# KM1M7CF03 register map
Vendor: Nuvoton Technology Corporation Japan; Series: KM1M7CF; File version: 1.0.3
CPU: CM7 r1p2, little endian, MPU, FPU, double-precision FPU, I-cache, D-cache, ITCM, DTCM, 4 interrupt priority bits
Registers are 16-bit, access per field, no defined reset value unless marked. A register's access mark holds for its fields unless they carry their own. Offsets are from the block's base; [hi:lo] are bit positions; {n}, {i} and the like mark numbered series; 'fields as' and 'values as' point back to an identical list.

## _16TM — 16-bit Timer
Base 0x40051000
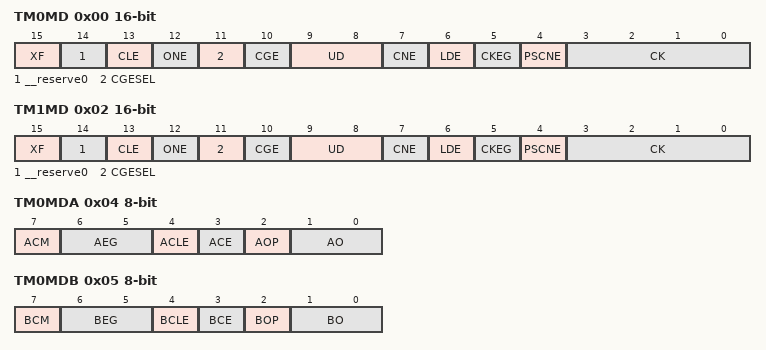
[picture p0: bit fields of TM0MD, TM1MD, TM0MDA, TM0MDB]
0x00 TM0MD — Timer 0 Mode Register
  [15] XF ro — Operation status of the timer n
  [14] __reserve0 ro — "0" is always read out.
  [13] CLE rw — Binary counter clear enable
  [12] ONE rw — Timer 1-shot operation enable
  [11] CGESEL rw — Timer count control selection
  [10] CGE rw — count clock mask enable
  [9:8] UD rw — Binary counter up/down selection
  [7] CNE rw — Timer n operation enable (*1)
  [6] LDE rw — Timer n binary counter initialization
  [5] CKEG rw — Clock Source Edge Selection
  [4] PSCNE rw — Prescaler operation enable
  [3:0] CK rw — Clock Source Selection
0x02 TM1MD — Timer 1 Mode Register
  fields as TM0MD
0x04 TM0MDA 8-bit rw — Timer 0 Compare/Capture A Mode Register
  [7] ACM — Compare A operation mode selection
  [6:5] AEG — Capture factor A edge selection
  [4] ACLE — Capture counter clear
  [3] ACE — Capture A operation enable
  [2] AOP — Timer output polarity
  [1:0] AO — Timer pin A output waveform selection
0x05 TM0MDB 8-bit rw — Timer 0 Compare/Capture B Mode Register
  [7] BCM — Compare B operation mode selection
  [6:5] BEG — Capture factor B edge selection
  [4] BCLE — Capture counter clear
  [3] BCE — Capture B operation enable
  [2] BOP — Timer output polarity
  [1:0] BO — Timer pin A output waveform selection
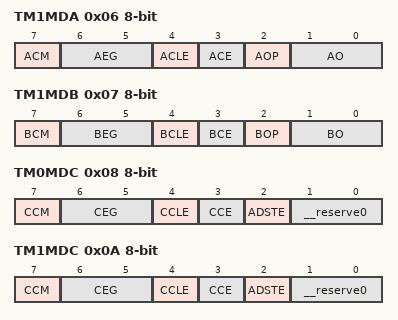
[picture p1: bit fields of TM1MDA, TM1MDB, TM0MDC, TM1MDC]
0x06 TM1MDA 8-bit rw — Timer 1 Compare/Capture A Mode Register
  fields as TM0MDA
0x07 TM1MDB 8-bit rw — Timer 1 Compare/Capture B Mode Register
  fields as TM0MDB
0x08 TM0MDC 8-bit — Timer 0 Compare/Capture C Mode Register
  [7] CCM rw — Compare C operation mode selection
  [6:5] CEG rw — Capture factor C edge selection
  [4] CCLE rw — Capture counter clear
  [3] CCE rw — Capture C operation enable
  [2] ADSTE rw — A/D start trigger enable
  [1:0] __reserve0 ro — "0" is always read out.
0x0A TM1MDC 8-bit — Timer 1 Compare/Capture C Mode Register
  fields as TM0MDC
0x10 TM0BC ro — Timer 0 Binary Counter
  [15:0] BC — Value of the binary counter is read out.
0x12 TM1BC ro — Timer 1 Binary Counter
  [15:0] BC — Value of the binary counter is read out.
0x14 TM0CA rw — Timer 0 Compare/Capture A Register
  [15:0] CA — Registers for compare A and capture A operation.
0x16 TM1CA rw — Timer 1 Compare/Capture A Register
  [15:0] CA — Registers for compare A and capture A operation.
0x18 TM0CB rw — Timer 0 Compare/Capture B Register
  [15:0] CB — Registers for compare B and capture B operation.
0x1A TM1CB rw — Timer 1 Compare/Capture B Register
  [15:0] CB — Registers for compare B and capture B operation.
0x1C TM0CC rw — Timer 0 Compare/Capture C Register
  [15:0] CC — Registers for compare C and capture C operation.
0x1E TM1CC rw — Timer 1 Compare/Capture C Register
  [15:0] CC — Registers for compare C and capture C operation.
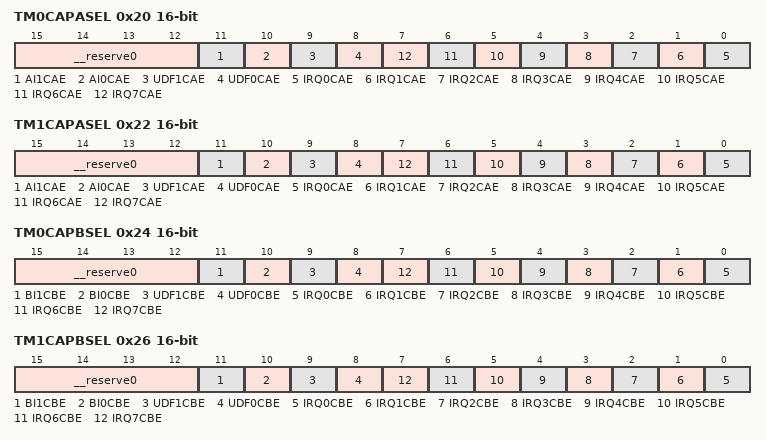
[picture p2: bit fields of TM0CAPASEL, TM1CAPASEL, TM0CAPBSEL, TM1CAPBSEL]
0x20 TM0CAPASEL — Timer 0 Capture A Factor Selection Register
  [15:12] __reserve0 ro — "0" is always read out.
  [11] AI1CAE rw — The capture A factor selection of timer n.
  [10] AI0CAE rw — The capture A factor selection of timer n.
  [9] UDF1CAE rw — The capture A factor selection of timer n.
  [8] UDF0CAE rw — The capture A factor selection of timer n.
  [n] IRQ{n}CAE rw (n=0..7) — The capture A factor selection of timer n.
0x22 TM1CAPASEL — Timer 1 Capture A Factor Selection Register
  fields as TM0CAPASEL
0x24 TM0CAPBSEL — Timer 0 Capture B Factor Selection Register
  [15:12] __reserve0 ro — "0" is always read out.
  [11] BI1CBE rw — The capture B factor selection of timer n
  [10] BI0CBE rw — The capture B factor selection of timer n
  [9] UDF1CBE rw — The capture B factor selection of timer n
  [8] UDF0CBE rw — The capture B factor selection of timer n
  [n] IRQ{n}CBE rw (n=0..7) — The capture B factor selection of timer n
0x26 TM1CAPBSEL — Timer 1 Capture B Factor Selection Register
  fields as TM0CAPBSEL
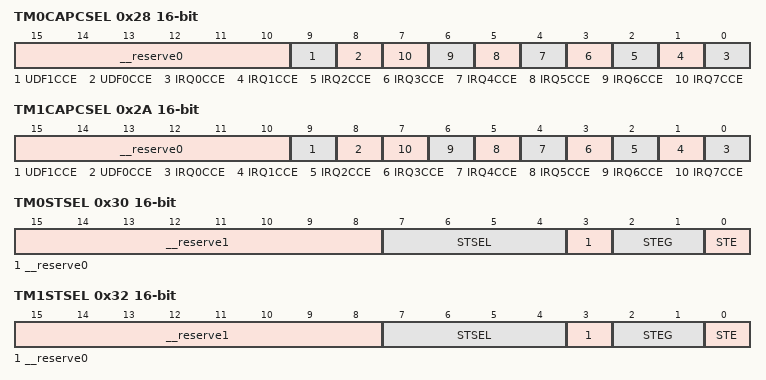
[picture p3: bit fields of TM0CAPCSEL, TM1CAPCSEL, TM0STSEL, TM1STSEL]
0x28 TM0CAPCSEL — Timer 0 Capture C Factor Selection Register
  [15:10] __reserve0 ro — "0" is always read out.
  [9] UDF1CCE rw — The capture C factor selection of timer n
  [8] UDF0CCE rw — The capture C factor selection of timer n
  [n] IRQ{n}CCE rw (n=0..7) — The capture C factor selection of timer n
0x2A TM1CAPCSEL — Timer 1 Capture C Factor Selection Register
  fields as TM0CAPCSEL
0x30 TM0STSEL — Timer 0 Start Trigger Factor Selection Register
  [15:8] __reserve1 ro — "0" is always read out.
  [7:4] STSEL rw — Start trigger factor selection
  [3] __reserve0 ro — "0" is always read out.
  [2:1] STEG rw — Start trigger factor edge selection
  [0] STE rw — Timer n start trigger enable
0x32 TM1STSEL — Timer 1 Start Trigger Factor Selection Register
  fields as TM0STSEL
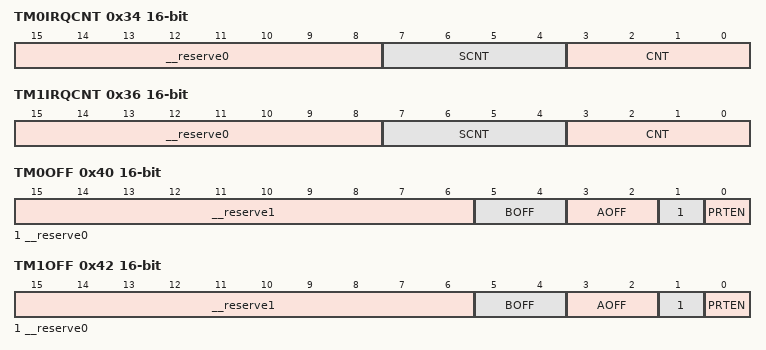
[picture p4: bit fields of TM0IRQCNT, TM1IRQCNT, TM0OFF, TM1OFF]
0x34 TM0IRQCNT — Timer 0 Interrupt Output Control Register
  [15:8] __reserve0 ro — "0" is always read out.
  [7:4] SCNT rw — Number of times setting for timer n compare/capture C interrupt (First time)
  [3:0] CNT rw — Number of times setting for timer n compare/capture C interrupt (Second time or later)
0x36 TM1IRQCNT — Timer 1 Interrupt Output Control Register
  fields as TM0IRQCNT
0x40 TM0OFF — Timer 0 Pin Protection Control Register
  [15:6] __reserve1 ro — "0" is always read out.
  [5:4] BOFF rw — TMnB pin output protection
  [3:2] AOFF rw — TMnA pin output protection
  [1] __reserve0 ro — "0" is always read out.
  [0] PRTEN rw — Pin protection enable
0x42 TM1OFF — Timer 1 Pin Protection Control Register
  fields as TM0OFF
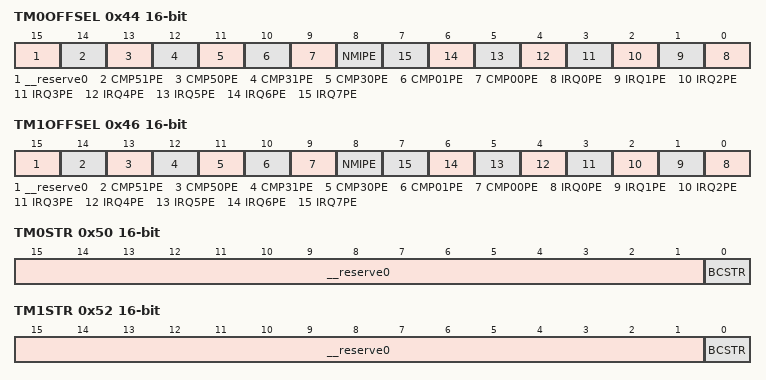
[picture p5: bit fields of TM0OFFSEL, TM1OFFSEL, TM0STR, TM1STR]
0x44 TM0OFFSEL rw — Timer 0 Pin Protection Factor Selection Register
  [15] __reserve0 — "0" is always read out.
  [14] CMP51PE — Protection factor selection by CMP51
  [13] CMP50PE — Protection factor selection by CMP50
  [12] CMP31PE — Protection factor selection by CMP31
  [11] CMP30PE — Protection factor selection by CMP30
  [10] CMP01PE — Protection factor selection by CMP01
  [9] CMP00PE — Protection factor selection by CMP00
  [8] NMIPE — Protection factor selection by NMI
  [n] IRQ{n}PE (n=0..7) — Protection factor selection by IRQ{n:02}
0x46 TM1OFFSEL rw — Timer 1 Pin Protection Factor Selection Register
  fields as TM0OFFSEL
0x50 TM0STR ro — Timer 0 Count Direction Status Register
  [15:1] __reserve0 — "0" is always read out.
  [0] BCSTR — The count direction of binary counter
0x52 TM1STR ro — Timer 1 Count Direction Status Register
  fields as TM0STR
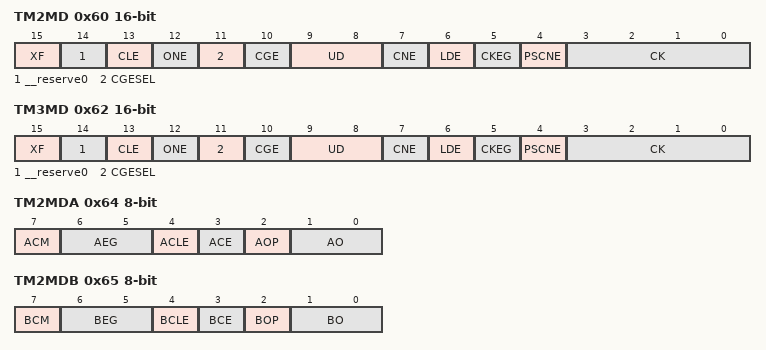
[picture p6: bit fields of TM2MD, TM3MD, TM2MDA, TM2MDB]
0x60 TM2MD — Timer 2 Mode Register
  fields as TM0MD
0x62 TM3MD — Timer 3 Mode Register
  fields as TM0MD
0x64 TM2MDA 8-bit rw — Timer 2 Compare/Capture A Mode Register
  fields as TM0MDA
0x65 TM2MDB 8-bit rw — Timer 2 Compare/Capture B Mode Register
  fields as TM0MDB
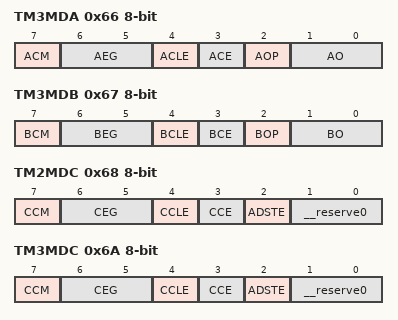
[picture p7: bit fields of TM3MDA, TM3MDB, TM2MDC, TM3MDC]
0x66 TM3MDA 8-bit rw — Timer 3 Compare/Capture A Mode Register
  fields as TM0MDA
0x67 TM3MDB 8-bit rw — Timer 3 Compare/Capture B Mode Register
  fields as TM0MDB
0x68 TM2MDC 8-bit — Timer 2 Compare/Capture C Mode Register
  fields as TM0MDC
0x6A TM3MDC 8-bit — Timer 3 Compare/Capture C Mode Register
  fields as TM0MDC
0x70 TM2BC ro — Timer 2 Binary Counter
  [15:0] BC — Value of the binary counter is read out.
0x72 TM3BC ro — Timer 3 Binary Counter
  [15:0] BC — Value of the binary counter is read out.
0x74 TM2CA rw — Timer 2 Compare/Capture A Register
  [15:0] CA — Registers for compare A and capture A operation.
0x76 TM3CA rw — Timer 3 Compare/Capture A Register
  [15:0] CA — Registers for compare A and capture A operation.
0x78 TM2CB rw — Timer 2 Compare/Capture B Register
  [15:0] CB — Registers for compare B and capture B operation.
0x7A TM3CB rw — Timer 3 Compare/Capture B Register
  [15:0] CB — Registers for compare B and capture B operation.
0x7C TM2CC rw — Timer 2 Compare/Capture C Register
  [15:0] CC — Registers for compare C and capture C operation.
0x7E TM3CC rw — Timer 3 Compare/Capture C Register
  [15:0] CC — Registers for compare C and capture C operation.
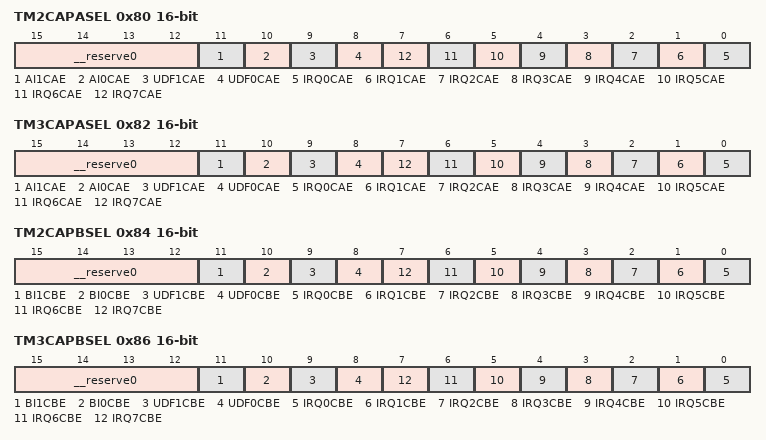
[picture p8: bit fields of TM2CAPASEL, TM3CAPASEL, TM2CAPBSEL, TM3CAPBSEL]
0x80 TM2CAPASEL — Timer 2 Capture A Factor Selection Register
  fields as TM0CAPASEL
0x82 TM3CAPASEL — Timer 3 Capture A Factor Selection Register
  fields as TM0CAPASEL
0x84 TM2CAPBSEL — Timer 2 Capture B Factor Selection Register
  fields as TM0CAPBSEL
0x86 TM3CAPBSEL — Timer 3 Capture B Factor Selection Register
  fields as TM0CAPBSEL
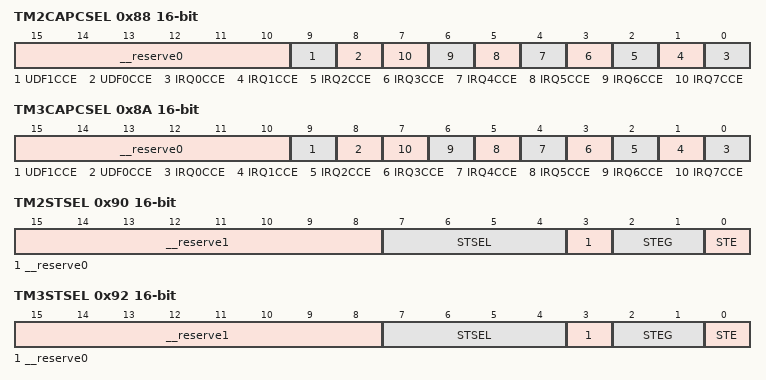
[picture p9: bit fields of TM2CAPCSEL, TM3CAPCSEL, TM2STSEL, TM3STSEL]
0x88 TM2CAPCSEL — Timer 2 Capture C Factor Selection Register
  fields as TM0CAPCSEL
0x8A TM3CAPCSEL — Timer 3 Capture C Factor Selection Register
  fields as TM0CAPCSEL
0x90 TM2STSEL — Timer 2 Start Trigger Factor Selection Register
  fields as TM0STSEL
0x92 TM3STSEL — Timer 3 Start Trigger Factor Selection Register
  fields as TM0STSEL
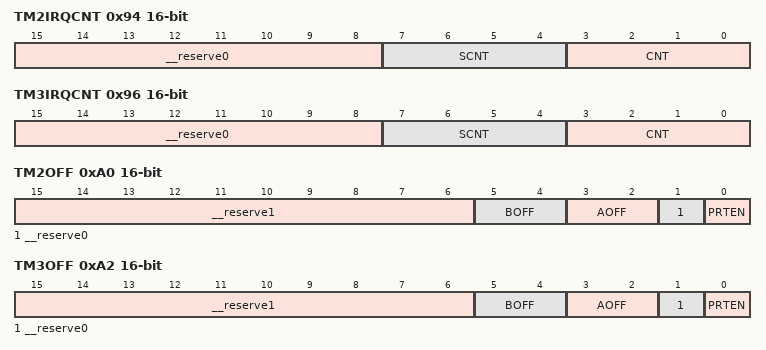
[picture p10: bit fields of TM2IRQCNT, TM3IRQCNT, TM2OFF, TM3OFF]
0x94 TM2IRQCNT — Timer 2 Interrupt Output Control Register
  fields as TM0IRQCNT
0x96 TM3IRQCNT — Timer 3 Interrupt Output Control Register
  fields as TM0IRQCNT
0xA0 TM2OFF — Timer 2 Pin Protection Control Register
  fields as TM0OFF
0xA2 TM3OFF — Timer 3 Pin Protection Control Register
  fields as TM0OFF
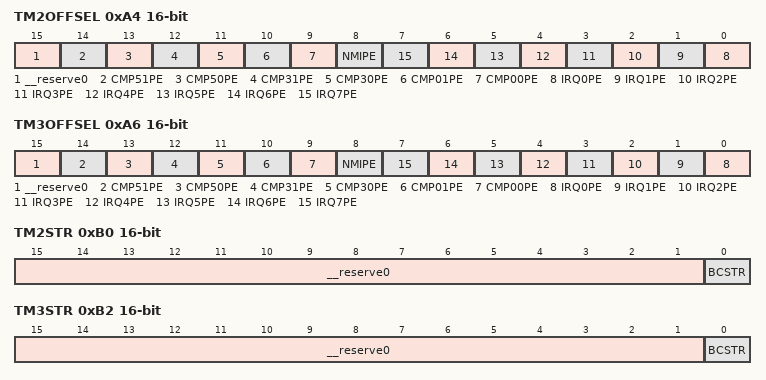
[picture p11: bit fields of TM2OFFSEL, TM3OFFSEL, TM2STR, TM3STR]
0xA4 TM2OFFSEL rw — Timer 2 Pin Protection Factor Selection Register
  fields as TM0OFFSEL
0xA6 TM3OFFSEL rw — Timer 3 Pin Protection Factor Selection Register
  fields as TM0OFFSEL
0xB0 TM2STR ro — Timer 2 Count Direction Status Register
  fields as TM0STR
0xB2 TM3STR ro — Timer 3 Count Direction Status Register
  fields as TM0STR
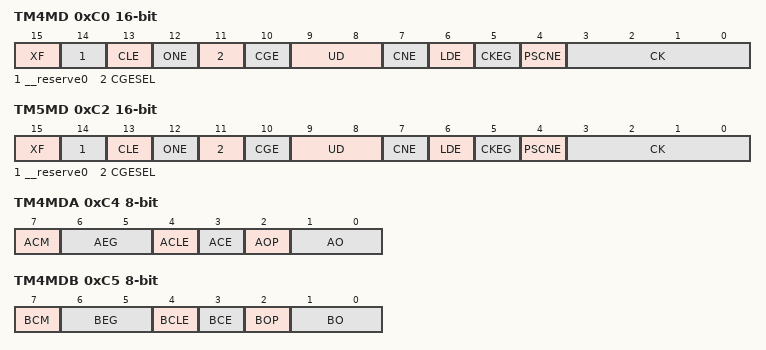
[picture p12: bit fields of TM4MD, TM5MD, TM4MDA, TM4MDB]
0xC0 TM4MD — Timer 4 Mode Register
  fields as TM0MD
0xC2 TM5MD — Timer 5 Mode Register
  fields as TM0MD
0xC4 TM4MDA 8-bit rw — Timer 4 Compare/Capture A Mode Register
  fields as TM0MDA
0xC5 TM4MDB 8-bit rw — Timer 4 Compare/Capture B Mode Register
  fields as TM0MDB
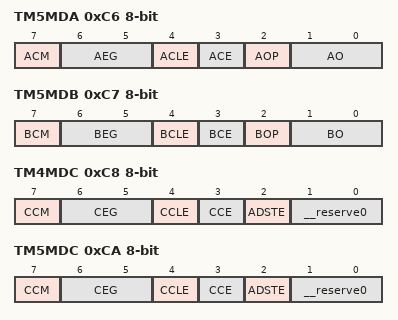
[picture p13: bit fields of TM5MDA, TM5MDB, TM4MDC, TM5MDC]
0xC6 TM5MDA 8-bit rw — Timer 5 Compare/Capture A Mode Register
  fields as TM0MDA
0xC7 TM5MDB 8-bit rw — Timer 5 Compare/Capture B Mode Register
  fields as TM0MDB
0xC8 TM4MDC 8-bit — Timer 4 Compare/Capture C Mode Register
  fields as TM0MDC
0xCA TM5MDC 8-bit — Timer 5 Compare/Capture C Mode Register
  fields as TM0MDC
0xD0 TM4BC ro — Timer 4 Binary Counter
  [15:0] BC — Value of the binary counter is read out.
0xD2 TM5BC ro — Timer 5 Binary Counter
  [15:0] BC — Value of the binary counter is read out.
0xD4 TM4CA rw — Timer 4 Compare/Capture A Register
  [15:0] CA — Registers for compare A and capture A operation.
0xD6 TM5CA rw — Timer 5 Compare/Capture A Register
  [15:0] CA — Registers for compare A and capture A operation.
0xD8 TM4CB rw — Timer 4 Compare/Capture B Register
  [15:0] CB — Registers for compare B and capture B operation.
0xDA TM5CB rw — Timer 5 Compare/Capture B Register
  [15:0] CB — Registers for compare B and capture B operation.
0xDC TM4CC rw — Timer 4 Compare/Capture C Register
  [15:0] CC — Registers for compare C and capture C operation.
0xDE TM5CC rw — Timer 5 Compare/Capture C Register
  [15:0] CC — Registers for compare C and capture C operation.
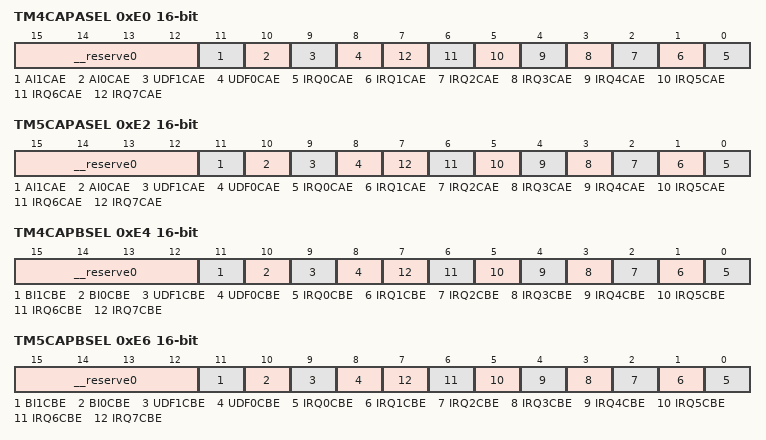
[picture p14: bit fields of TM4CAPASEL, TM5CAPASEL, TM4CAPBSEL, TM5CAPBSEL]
0xE0 TM4CAPASEL — Timer 4 Capture A Factor Selection Register
  fields as TM0CAPASEL
0xE2 TM5CAPASEL — Timer 5 Capture A Factor Selection Register
  fields as TM0CAPASEL
0xE4 TM4CAPBSEL — Timer 4 Capture B Factor Selection Register
  fields as TM0CAPBSEL
0xE6 TM5CAPBSEL — Timer 5 Capture B Factor Selection Register
  fields as TM0CAPBSEL
0xE8 TM4CAPCSEL — Timer 4 Capture C Factor Selection Register
  fields as TM0CAPCSEL
0xEA TM5CAPCSEL — Timer 5 Capture C Factor Selection Register
  fields as TM0CAPCSEL
0xF0 TM4STSEL — Timer 4 Start Trigger Factor Selection Register
  fields as TM0STSEL
0xF2 TM5STSEL — Timer 5 Start Trigger Factor Selection Register
  fields as TM0STSEL
0xF4 TM4IRQCNT — Timer 4 Interrupt Output Control Register
  fields as TM0IRQCNT
0xF6 TM5IRQCNT — Timer 5 Interrupt Output Control Register
  fields as TM0IRQCNT
0x100 TM4OFF — Timer 4 Pin Protection Control Register
  fields as TM0OFF
0x102 TM5OFF — Timer 5 Pin Protection Control Register
  fields as TM0OFF
0x104 TM4OFFSEL rw — Timer 4 Pin Protection Factor Selection Register
  fields as TM0OFFSEL
0x106 TM5OFFSEL rw — Timer 5 Pin Protection Factor Selection Register
  fields as TM0OFFSEL
0x110 TM4STR ro — Timer 4 Count Direction Status Register
  fields as TM0STR
0x112 TM5STR ro — Timer 5 Count Direction Status Register
  fields as TM0STR
0x120 TM6MD — Timer 6 Mode Register
  fields as TM0MD
0x122 TM7MD — Timer 7 Mode Register
  fields as TM0MD
0x124 TM6MDA 8-bit rw — Timer 6 Compare/Capture A Mode Register
  fields as TM0MDA
0x125 TM6MDB 8-bit rw — Timer 6 Compare/Capture B Mode Register
  fields as TM0MDB
0x126 TM7MDA 8-bit rw — Timer 7 Compare/Capture A Mode Register
  fields as TM0MDA
0x127 TM7MDB 8-bit rw — Timer 7 Compare/Capture B Mode Register
  fields as TM0MDB
0x128 TM6MDC 8-bit — Timer 6 Compare/Capture C Mode Register
  fields as TM0MDC
0x12A TM7MDC 8-bit — Timer 7 Compare/Capture C Mode Register
  fields as TM0MDC
0x130 TM6BC ro — Timer 6 Binary Counter
  [15:0] BC — Value of the binary counter is read out.
0x132 TM7BC ro — Timer 7 Binary Counter
  [15:0] BC — Value of the binary counter is read out.
0x134 TM6CA rw — Timer 6 Compare/Capture A Register
  [15:0] CA — Registers for compare A and capture A operation.
0x136 TM7CA rw — Timer 7 Compare/Capture A Register
  [15:0] CA — Registers for compare A and capture A operation.
0x138 TM6CB rw — Timer 6 Compare/Capture B Register
  [15:0] CB — Registers for compare B and capture B operation.
0x13A TM7CB rw — Timer 7 Compare/Capture B Register
  [15:0] CB — Registers for compare B and capture B operation.
0x13C TM6CC rw — Timer 6 Compare/Capture C Register
  [15:0] CC — Registers for compare C and capture C operation.
0x13E TM7CC rw — Timer 7 Compare/Capture C Register
  [15:0] CC — Registers for compare C and capture C operation.
0x140 TM6CAPASEL — Timer 6 Capture A Factor Selection Register
  fields as TM0CAPASEL
0x142 TM7CAPASEL — Timer 7 Capture A Factor Selection Register
  fields as TM0CAPASEL
0x144 TM6CAPBSEL — Timer 6 Capture B Factor Selection Register
  fields as TM0CAPBSEL
0x146 TM7CAPBSEL — Timer 7 Capture B Factor Selection Register
  fields as TM0CAPBSEL
0x148 TM6CAPCSEL — Timer 6 Capture C Factor Selection Register
  fields as TM0CAPCSEL
0x14A TM7CAPCSEL — Timer 7 Capture C Factor Selection Register
  fields as TM0CAPCSEL
0x150 TM6STSEL — Timer 6 Start Trigger Factor Selection Register
  fields as TM0STSEL
0x152 TM7STSEL — Timer 7 Start Trigger Factor Selection Register
  fields as TM0STSEL
0x154 TM6IRQCNT — Timer 6 Interrupt Output Control Register
  fields as TM0IRQCNT
0x156 TM7IRQCNT — Timer 7 Interrupt Output Control Register
  fields as TM0IRQCNT
0x160 TM6OFF — Timer 6 Pin Protection Control Register
  fields as TM0OFF
0x162 TM7OFF — Timer 7 Pin Protection Control Register
  fields as TM0OFF
0x164 TM6OFFSEL rw — Timer 6 Pin Protection Factor Selection Register
  fields as TM0OFFSEL
0x166 TM7OFFSEL rw — Timer 7 Pin Protection Factor Selection Register
  fields as TM0OFFSEL
0x170 TM6STR ro — Timer 6 Count Direction Status Register
  fields as TM0STR
0x172 TM7STR ro — Timer 7 Count Direction Status Register
  fields as TM0STR
0x180 TM8MD — Timer 8 Mode Register
  fields as TM0MD
0x182 TM9MD — Timer 9 Mode Register
  fields as TM0MD
0x184 TM8MDA 8-bit rw — Timer 8 Compare/Capture A Mode Register
  fields as TM0MDA
0x185 TM8MDB 8-bit rw — Timer 8 Compare/Capture B Mode Register
  fields as TM0MDB
0x186 TM9MDA 8-bit rw — Timer 9 Compare/Capture A Mode Register
  fields as TM0MDA
0x187 TM9MDB 8-bit rw — Timer 9 Compare/Capture B Mode Register
  fields as TM0MDB
0x188 TM8MDC 8-bit — Timer 8 Compare/Capture C Mode Register
  fields as TM0MDC
0x18A TM9MDC 8-bit — Timer 9 Compare/Capture C Mode Register
  fields as TM0MDC
0x190 TM8BC ro — Timer 8 Binary Counter
  [15:0] BC — Value of the binary counter is read out.
0x192 TM9BC ro — Timer 9 Binary Counter
  [15:0] BC — Value of the binary counter is read out.
0x194 TM8CA rw — Timer 8 Compare/Capture A Register
  [15:0] CA — Registers for compare A and capture A operation.
0x196 TM9CA rw — Timer 9 Compare/Capture A Register
  [15:0] CA — Registers for compare A and capture A operation.
0x198 TM8CB rw — Timer 8 Compare/Capture B Register
  [15:0] CB — Registers for compare B and capture B operation.
0x19A TM9CB rw — Timer 9 Compare/Capture B Register
  [15:0] CB — Registers for compare B and capture B operation.
0x19C TM8CC rw — Timer 8 Compare/Capture C Register
  [15:0] CC — Registers for compare C and capture C operation.
0x19E TM9CC rw — Timer 9 Compare/Capture C Register
  [15:0] CC — Registers for compare C and capture C operation.
0x1A0 TM8CAPASEL — Timer 8 Capture A Factor Selection Register
  fields as TM0CAPASEL
0x1A2 TM9CAPASEL — Timer 9 Capture A Factor Selection Register
  fields as TM0CAPASEL
0x1A4 TM8CAPBSEL — Timer 8 Capture B Factor Selection Register
  fields as TM0CAPBSEL
0x1A6 TM9CAPBSEL — Timer 9 Capture B Factor Selection Register
  fields as TM0CAPBSEL
0x1A8 TM8CAPCSEL — Timer 8 Capture C Factor Selection Register
  fields as TM0CAPCSEL
0x1AA TM9CAPCSEL — Timer 9 Capture C Factor Selection Register
  fields as TM0CAPCSEL
0x1B0 TM8STSEL — Timer 8 Start Trigger Factor Selection Register
  fields as TM0STSEL
0x1B2 TM9STSEL — Timer 9 Start Trigger Factor Selection Register
  fields as TM0STSEL
0x1B4 TM8IRQCNT — Timer 8 Interrupt Output Control Register
  fields as TM0IRQCNT
0x1B6 TM9IRQCNT — Timer 9 Interrupt Output Control Register
  fields as TM0IRQCNT
0x1C0 TM8OFF — Timer 8 Pin Protection Control Register
  fields as TM0OFF
0x1C2 TM9OFF — Timer 9 Pin Protection Control Register
  fields as TM0OFF
0x1C4 TM8OFFSEL rw — Timer 8 Pin Protection Factor Selection Register
  fields as TM0OFFSEL
0x1C6 TM9OFFSEL rw — Timer 9 Pin Protection Factor Selection Register
  fields as TM0OFFSEL
0x1D0 TM8STR ro — Timer 8 Count Direction Status Register
  fields as TM0STR
0x1D2 TM9STR ro — Timer 9 Count Direction Status Register
  fields as TM0STR
0x1E0 TM10MD — Timer 10 Mode Register
  fields as TM0MD
0x1E2 TM11MD — Timer 11 Mode Register
  fields as TM0MD
0x1E4 TM10MDA 8-bit rw — Timer 10 Compare/Capture A Mode Register
  fields as TM0MDA
0x1E5 TM10MDB 8-bit rw — Timer 10 Compare/Capture B Mode Register
  fields as TM0MDB
0x1E6 TM11MDA 8-bit rw — Timer 11 Compare/Capture A Mode Register
  fields as TM0MDA
0x1E7 TM11MDB 8-bit rw — Timer 11 Compare/Capture B Mode Register
  fields as TM0MDB
0x1E8 TM10MDC 8-bit — Timer 10 Compare/Capture C Mode Register
  fields as TM0MDC
0x1EA TM11MDC 8-bit — Timer 11 Compare/Capture C Mode Register
  fields as TM0MDC
0x1F0 TM10BC ro — Timer 10 Binary Counter
  [15:0] BC — Value of the binary counter is read out.
0x1F2 TM11BC ro — Timer 11 Binary Counter
  [15:0] BC — Value of the binary counter is read out.
0x1F4 TM10CA rw — Timer 10 Compare/Capture A Register
  [15:0] CA — Registers for compare A and capture A operation.
0x1F6 TM11CA rw — Timer 11 Compare/Capture A Register
  [15:0] CA — Registers for compare A and capture A operation.
0x1F8 TM10CB rw — Timer 10 Compare/Capture B Register
  [15:0] CB — Registers for compare B and capture B operation.
0x1FA TM11CB rw — Timer 11 Compare/Capture B Register
  [15:0] CB — Registers for compare B and capture B operation.
0x1FC TM10CC rw — Timer 10 Compare/Capture C Register
  [15:0] CC — Registers for compare C and capture C operation.
0x1FE TM11CC rw — Timer 11 Compare/Capture C Register
  [15:0] CC — Registers for compare C and capture C operation.
0x200 TM10CAPASEL — Timer 10 Capture A Factor Selection Register
  fields as TM0CAPASEL
0x202 TM11CAPASEL — Timer 11 Capture A Factor Selection Register
  fields as TM0CAPASEL
0x204 TM10CAPBSEL — Timer 10 Capture B Factor Selection Register
  fields as TM0CAPBSEL
0x206 TM11CAPBSEL — Timer 11 Capture B Factor Selection Register
  fields as TM0CAPBSEL
0x208 TM10CAPCSEL — Timer 10 Capture C Factor Selection Register
  fields as TM0CAPCSEL
0x20A TM11CAPCSEL — Timer 11 Capture C Factor Selection Register
  fields as TM0CAPCSEL
0x210 TM10STSEL — Timer 10 Start Trigger Factor Selection Register
  fields as TM0STSEL
0x212 TM11STSEL — Timer 11 Start Trigger Factor Selection Register
  fields as TM0STSEL
0x214 TM10IRQCNT — Timer 10 Interrupt Output Control Register
  fields as TM0IRQCNT
0x216 TM11IRQCNT — Timer 11 Interrupt Output Control Register
  fields as TM0IRQCNT
0x220 TM10OFF — Timer 10 Pin Protection Control Register
  fields as TM0OFF
0x222 TM11OFF — Timer 11 Pin Protection Control Register
  fields as TM0OFF
0x224 TM10OFFSEL rw — Timer 10 Pin Protection Factor Selection Register
  fields as TM0OFFSEL
0x226 TM11OFFSEL rw — Timer 11 Pin Protection Factor Selection Register
  fields as TM0OFFSEL
0x230 TM10STR ro — Timer 10 Count Direction Status Register
  fields as TM0STR
0x232 TM11STR ro — Timer 11 Count Direction Status Register
  fields as TM0STR
0x240 TM12MD — Timer 12 Mode Register
  fields as TM0MD
0x242 TM13MD — Timer 13 Mode Register
  fields as TM0MD
0x244 TM12MDA 8-bit rw — Timer 12 Compare/Capture A Mode Register
  fields as TM0MDA
0x245 TM12MDB 8-bit rw — Timer 12 Compare/Capture B Mode Register
  fields as TM0MDB
0x246 TM13MDA 8-bit rw — Timer 13 Compare/Capture A Mode Register
  fields as TM0MDA
0x247 TM13MDB 8-bit rw — Timer 13 Compare/Capture B Mode Register
  fields as TM0MDB
0x248 TM12MDC 8-bit — Timer 12 Compare/Capture C Mode Register
  fields as TM0MDC
0x24A TM13MDC 8-bit — Timer 13 Compare/Capture C Mode Register
  fields as TM0MDC
0x250 TM12BC ro — Timer 12 Binary Counter
  [15:0] BC — Value of the binary counter is read out.
0x252 TM13BC ro — Timer 13 Binary Counter
  [15:0] BC — Value of the binary counter is read out.
0x254 TM12CA rw — Timer 12 Compare/Capture A Register
  [15:0] CA — Registers for compare A and capture A operation.
0x256 TM13CA rw — Timer 13 Compare/Capture A Register
  [15:0] CA — Registers for compare A and capture A operation.
0x258 TM12CB rw — Timer 12 Compare/Capture B Register
  [15:0] CB — Registers for compare B and capture B operation.
0x25A TM13CB rw — Timer 13 Compare/Capture B Register
  [15:0] CB — Registers for compare B and capture B operation.
0x25C TM12CC rw — Timer 12 Compare/Capture C Register
  [15:0] CC — Registers for compare C and capture C operation.
0x25E TM13CC rw — Timer 13 Compare/Capture C Register
  [15:0] CC — Registers for compare C and capture C operation.
0x260 TM12CAPASEL — Timer 12 Capture A Factor Selection Register
  fields as TM0CAPASEL
0x262 TM13CAPASEL — Timer 13 Capture A Factor Selection Register
  fields as TM0CAPASEL
0x264 TM12CAPBSEL — Timer 12 Capture B Factor Selection Register
  fields as TM0CAPBSEL
0x266 TM13CAPBSEL — Timer 13 Capture B Factor Selection Register
  fields as TM0CAPBSEL
0x268 TM12CAPCSEL — Timer 12 Capture C Factor Selection Register
  fields as TM0CAPCSEL
0x26A TM13CAPCSEL — Timer 13 Capture C Factor Selection Register
  fields as TM0CAPCSEL
0x270 TM12STSEL — Timer 12 Start Trigger Factor Selection Register
  fields as TM0STSEL
0x272 TM13STSEL — Timer 13 Start Trigger Factor Selection Register
  fields as TM0STSEL
0x274 TM12IRQCNT — Timer 12 Interrupt Output Control Register
  fields as TM0IRQCNT
0x276 TM13IRQCNT — Timer 13 Interrupt Output Control Register
  fields as TM0IRQCNT
0x280 TM12OFF — Timer 12 Pin Protection Control Register
  fields as TM0OFF
0x282 TM13OFF — Timer 13 Pin Protection Control Register
  fields as TM0OFF
0x284 TM12OFFSEL rw — Timer 12 Pin Protection Factor Selection Register
  fields as TM0OFFSEL
0x286 TM13OFFSEL rw — Timer 13 Pin Protection Factor Selection Register
  fields as TM0OFFSEL
0x290 TM12STR ro — Timer 12 Count Direction Status Register
  fields as TM0STR
0x292 TM13STR ro — Timer 13 Count Direction Status Register
  fields as TM0STR
